# XMC4300 register map
Vendor: Infineon; File version: 0.5.1 (Superset device XMC4800)
CPU: CM4 r2p0, little endian, MPU, FPU, 6 interrupt priority bits
Registers are 32-bit, read-write, reset 0x0 unless marked. A register's access mark holds for its fields unless they carry their own. Offsets are from the block's base; [hi:lo] are bit positions.

## SDMMC — SD and Multimediacard Interface
Base 0x4801C000
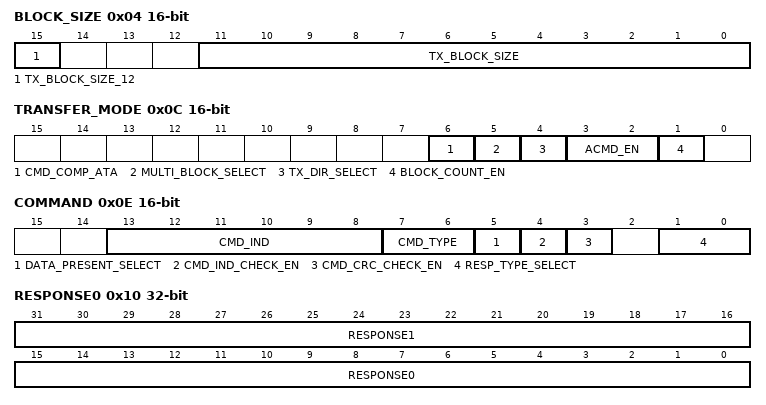
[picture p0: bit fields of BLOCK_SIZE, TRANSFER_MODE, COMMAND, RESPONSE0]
0x04 BLOCK_SIZE 16-bit
  [15] TX_BLOCK_SIZE_12 — Transfer Block Size 12th bit.
  [11:0] TX_BLOCK_SIZE — Transfer Block Size
0x06 BLOCK_COUNT 16-bit
  [15:0] BLOCK_COUNT — Blocks Count for Current Transfer
0x08 ARGUMENT1
  [31:0] ARGUMENT1 — Command Argument
0x0C TRANSFER_MODE 16-bit
  [6] CMD_COMP_ATA — Command Completion Signal Enable for CE-ATA Device
    1=Device will send command completion Signal; 0=Device will not send command completion Signal
  [5] MULTI_BLOCK_SELECT — Multi / Single Block Select
    0=Single Block; 1=Multiple Block
  [4] TX_DIR_SELECT — Data Transfer Direction Select
    0=Write (Host to Card); 1=Read (Card to Host)
  [3:2] ACMD_EN — Auto CMD Enable
    0=Auto Command Disabled; 1=Auto CMD12 Enable
  [1] BLOCK_COUNT_EN — Block Count Enable
    0=Disable; 1=Enable
0x0E COMMAND 16-bit
  [13:8] CMD_IND — Command Index
  [7:6] CMD_TYPE — Command Type
    0=Normal; 1=Suspend; 2=Resume; 3=Abort
  [5] DATA_PRESENT_SELECT
    0=No Data Present; 1=Data Present
  [4] CMD_IND_CHECK_EN — Command Index Check Enable
    0=Disable; 1=Enable
  [3] CMD_CRC_CHECK_EN — Command CRC Check Enable
    0=Disable; 1=Enable
  [1:0] RESP_TYPE_SELECT — Response Type Select
    0=No Response; 1=Response length 136; 2=Response length 48; 3=Response length 48 check Busy after response
0x10 RESPONSE0 ro
  [31:16] RESPONSE1, [15:0] RESPONSE0
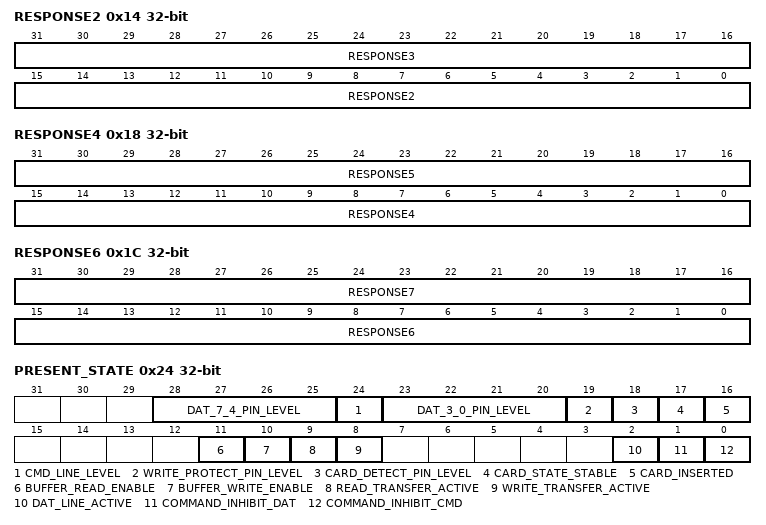
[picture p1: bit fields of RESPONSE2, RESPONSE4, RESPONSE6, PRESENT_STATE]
0x14 RESPONSE2 ro
  [31:16] RESPONSE3, [15:0] RESPONSE2
0x18 RESPONSE4 ro
  [31:16] RESPONSE5, [15:0] RESPONSE4
0x1C RESPONSE6 ro
  [31:16] RESPONSE7, [15:0] RESPONSE6
0x20 DATA_BUFFER
0x24 PRESENT_STATE ro
  [28:25] DAT_7_4_PIN_LEVEL — Line Signal Level
  [24] CMD_LINE_LEVEL — CMD Line Signal Level
  [23:20] DAT_3_0_PIN_LEVEL — Line Signal Level
  [19] WRITE_PROTECT_PIN_LEVEL — Write Protect Switch Pin Level
    0=Write protected (SDWP = 1); 1=Write enabled (SDWP = 0)
  [18] CARD_DETECT_PIN_LEVEL
    0=No Card present (SDCD = 1); 1=Card present (SDCD = 0)
  [17] CARD_STATE_STABLE
    0=Reset of Debouncing; 1=No Card or Inserted
  [16] CARD_INSERTED
    0=Reset or Debouncing or No Card; 1=Card Inserted
  [11] BUFFER_READ_ENABLE
    0=Read Disable; 1=Read Enable
  [10] BUFFER_WRITE_ENABLE
    0=Write Disable; 1=Write Enable
  [9] READ_TRANSFER_ACTIVE
    0=No valid data; 1=Transferring data
  [8] WRITE_TRANSFER_ACTIVE
    0=No valid data; 1=Transferring data
  [2] DAT_LINE_ACTIVE
    0=DAT line inactive; 1=DAT line active
  [1] COMMAND_INHIBIT_DAT
    0=Can issue command which uses the DAT line; 1=Cannot issue command which uses the DAT line
  [0] COMMAND_INHIBIT_CMD
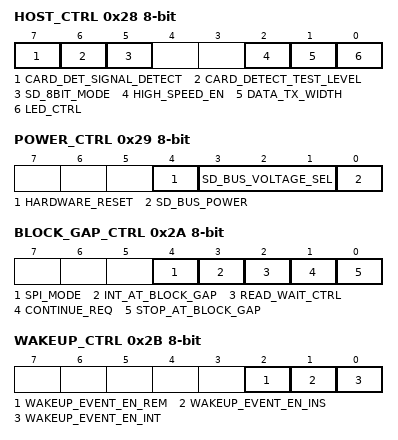
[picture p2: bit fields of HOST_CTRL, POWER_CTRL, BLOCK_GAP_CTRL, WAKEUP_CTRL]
0x28 HOST_CTRL 8-bit — Host Control Register
  [7] CARD_DET_SIGNAL_DETECT — Card detect signal detetction
    0=SDCD is selected (for normal use); 1=The card detect test level is selected
  [6] CARD_DETECT_TEST_LEVEL
    0=No Card; 1=Card Inserted
  [5] SD_8BIT_MODE — Extended Data Transfer Width
    0=Bus Width is selected by Data Transfer Width; 1=8-bit Bus Width
  [2] HIGH_SPEED_EN — High Speed Enable
    0=Normal Speed Mode; 1=High Speed Mode
  [1] DATA_TX_WIDTH — Data Transfer Width (SD1 or SD4)
    0=1 bit mode; 1=4-bit mode
  [0] LED_CTRL — LED Control
    0=LED off; 1=LED on
0x29 POWER_CTRL 8-bit — Power Control Register
  [4] HARDWARE_RESET
  [3:1] SD_BUS_VOLTAGE_SEL — SD Bus Voltage Select
    7=3.3V (Flattop.)
  [0] SD_BUS_POWER
    0=Power off; 1=Power on
0x2A BLOCK_GAP_CTRL 8-bit — Block Gap Control Register
  [4] SPI_MODE
    0=SD mode; 1=SPI mode
  [3] INT_AT_BLOCK_GAP — Interrupt At Block Gap
  [2] READ_WAIT_CTRL — Read Wait Control
    0=Disable Read Wait Control; 1=Enable Read Wait Control
  [1] CONTINUE_REQ — Continue Request
    0=Ignored; 1=Restart
  [0] STOP_AT_BLOCK_GAP — Stop At Block Gap Request
    0=Transfer; 1=Stop
0x2B WAKEUP_CTRL 8-bit — Wake-up Control Register
  [all] fields
    0=Disable; 1=Enable
  [2] WAKEUP_EVENT_EN_REM — Wakeup Event Enable On SD Card Removal
  [1] WAKEUP_EVENT_EN_INS — Wakeup Event Enable On SD Card Insertion
  [0] WAKEUP_EVENT_EN_INT — Wakeup Event Enable On Card Interrupt
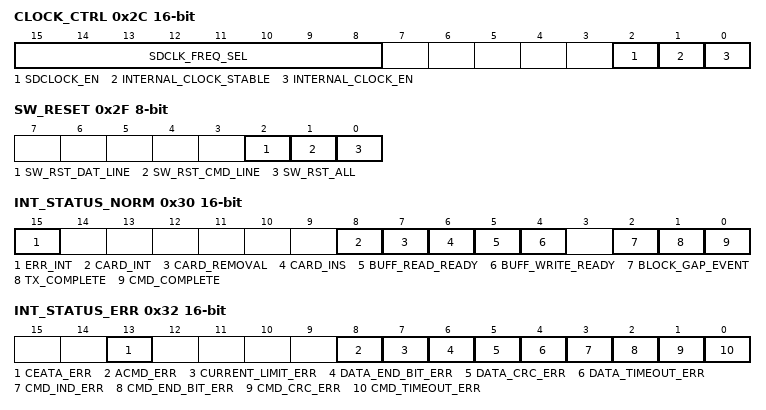
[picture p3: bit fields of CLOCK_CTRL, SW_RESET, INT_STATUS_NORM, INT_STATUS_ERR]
0x2C CLOCK_CTRL 16-bit access per field — Clock Control Register
  [15:8] SDCLK_FREQ_SEL rw — SDCLK Frequency Select
    0=base clock(10MHz-63MHz); 1=base clock divided by 2; 16=base clock divided by 32; 2=base clock divided by 4; 4=base clock divided by 8; 8=base clock divided by 16; 32=base clock divided by 64; 64=base clock divided by 128; 128=base clock divided by 256
  [2] SDCLOCK_EN rw — SD Clock Enable
    0=Disable; 1=Enable
  [1] INTERNAL_CLOCK_STABLE ro
    0=Not Ready; 1=Ready
  [0] INTERNAL_CLOCK_EN rw — Internal Clock Enable
    0=Stop; 1=Oscillate
0x2E TIMEOUT_CTRL 8-bit — Timeout Control Register
  [3:0] DAT_TIMEOUT_CNT_VAL — Data Timeout Counter Value
    0=TMCLK * 2^13; 1=TMCLK * 2^14; 14=TMCLK * 2^27
0x2F SW_RESET 8-bit — Software Reset Register
  [2] SW_RST_DAT_LINE — Software Reset for DAT Line
    0=Work; 1=Reset
  [1] SW_RST_CMD_LINE — Software Reset for CMD Line
    0=Work; 1=Reset
  [0] SW_RST_ALL — Software Reset for All
0x30 INT_STATUS_NORM 16-bit access per field — Normal Interrupt Status Register
  [15] ERR_INT ro — Error Interrupt
    0=No Error; 1=Error
  [8] CARD_INT ro — Card Interrupt
    0=No Card Interrupt; 1=Generate Card Interrupt
  [7] CARD_REMOVAL rw
    0=Card State Stable or Debouncing; 1=Card Removed
  [6] CARD_INS rw — Card Insertion
    0=Card State Stable or Debouncing; 1=Card Inserted
  [5] BUFF_READ_READY rw — Buffer Read Ready
    0=Not Ready to read Buffer; 1=Ready to read Buffer
  [4] BUFF_WRITE_READY rw — Buffer Write Ready
    0=Not Ready to Write Buffer; 1=Ready to Write Buffer
  [2] BLOCK_GAP_EVENT rw
    0=No Block Gap Event; 1=Transaction stopped at Block Gap
  [1] TX_COMPLETE rw — Transfer Complete
    0=No Data Transfer Complete; 1=Data Transfer Complete
  [0] CMD_COMPLETE rw — Command Complete
    0=No Command Complete; 1=Command Complete
0x32 INT_STATUS_ERR 16-bit — Error Interrupt Status Register
  [13] CEATA_ERR — Ceata Error Status
    0=no error; 1=error
  [8] ACMD_ERR — Auto CMD Error
    0=No Error; 1=Error
  [7] CURRENT_LIMIT_ERR — Current Limit Error
    0=No Error; 1=Power Fail
  [6] DATA_END_BIT_ERR — Data End Bit Error
    0=No Error; 1=Error
  [5] DATA_CRC_ERR — Data CRC Error
    0=No Error; 1=Error
  [4] DATA_TIMEOUT_ERR — Data Timeout Error
    0=No Error; 1=Timeout
  [3] CMD_IND_ERR — Command Index Error
    0=No Error; 1=Error
  [2] CMD_END_BIT_ERR — Command End Bit Error
    0=No Error; 1=End Bit Error Generated
  [1] CMD_CRC_ERR — Command CRC Error
    0=No Error; 1=CRC Error Generated
  [0] CMD_TIMEOUT_ERR — Command Timeout Error
    0=No Error; 1=Timeout
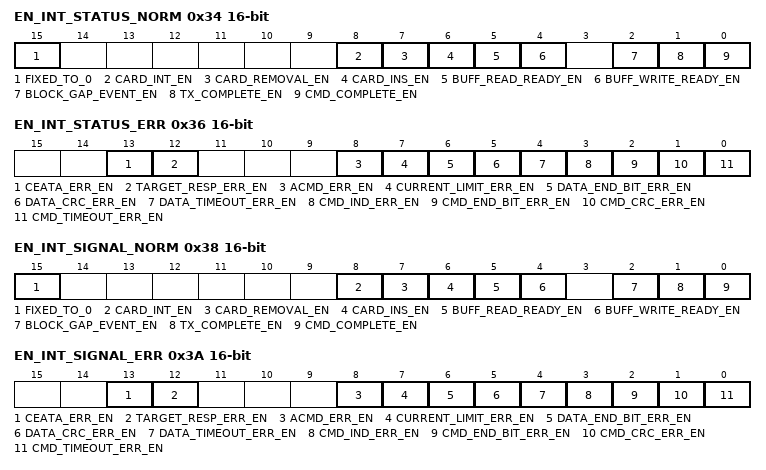
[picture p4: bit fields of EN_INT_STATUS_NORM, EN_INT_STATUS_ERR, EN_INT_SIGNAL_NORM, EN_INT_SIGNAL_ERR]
0x34 EN_INT_STATUS_NORM 16-bit access per field — Normal Interrupt Status Enable Register
  [15] FIXED_TO_0 ro
  [8] CARD_INT_EN rw — Card Interrupt Status Enable
    0=Masked; 1=Enabled
  [7] CARD_REMOVAL_EN rw — Card Removal Status Enable
    0=Masked; 1=Enabled
  [6] CARD_INS_EN rw — Card Insertion Status Enable
    0=Masked; 1=Enabled
  [5] BUFF_READ_READY_EN rw — Buffer Read Ready Status Enable
    0=Masked; 1=Enabled
  [4] BUFF_WRITE_READY_EN rw — Buffer Write Ready Status Enable
    0=Masked; 1=Enabled
  [2] BLOCK_GAP_EVENT_EN rw — Block Gap Event Status Enable
    0=Masked; 1=Enabled
  [1] TX_COMPLETE_EN rw — Transfer Complete Status Enable
    0=Masked; 1=Enabled
  [0] CMD_COMPLETE_EN rw — Command Complete Status Enable
    0=Masked; 1=Enabled
0x36 EN_INT_STATUS_ERR 16-bit — Error Interrupt Status Enable Register
  [all] fields
    0=Masked; 1=Enabled
  [13] CEATA_ERR_EN — Ceata Error Status Enable
  [12] TARGET_RESP_ERR_EN — Target Response Error Status Enable
  [8] ACMD_ERR_EN — Auto CMD12 Error Status Enable
  [7] CURRENT_LIMIT_ERR_EN — Current Limit Error Status Enable
  [6] DATA_END_BIT_ERR_EN — Data End Bit Error Status Enable
  [5] DATA_CRC_ERR_EN — Data CRC Error Status Enable
  [4] DATA_TIMEOUT_ERR_EN — Data Timeout Error Status Enable
  [3] CMD_IND_ERR_EN — Command Index Error Status Enable
  [2] CMD_END_BIT_ERR_EN — Command End Bit Error Status Enable
  [1] CMD_CRC_ERR_EN — Command CRC Error Status Enable
  [0] CMD_TIMEOUT_ERR_EN — Command Timeout Error Status Enable
0x38 EN_INT_SIGNAL_NORM 16-bit access per field — Normal Interrupt Signal Enable Register
  [15] FIXED_TO_0 ro
  [8] CARD_INT_EN rw — Card Interrupt Signal Enable
    0=Masked; 1=Enabled
  [7] CARD_REMOVAL_EN rw — Card Removal Signal Enable
    0=Masked; 1=Enabled
  [6] CARD_INS_EN rw — Card Insertion Signal Enable
    0=Masked; 1=Enabled
  [5] BUFF_READ_READY_EN rw — Buffer Read Ready Signal Enable
    0=Masked; 1=Enabled
  [4] BUFF_WRITE_READY_EN rw — Buffer Write Ready Signal Enable
    0=Masked; 1=Enabled
  [2] BLOCK_GAP_EVENT_EN rw — Block Gap Event Signal Enable
    0=Masked; 1=Enabled
  [1] TX_COMPLETE_EN rw — Transfer Complete Signal Enable
    0=Masked; 1=Enabled
  [0] CMD_COMPLETE_EN rw — Command Complete Signal Enable
    0=Masked; 1=Enabled
0x3A EN_INT_SIGNAL_ERR 16-bit — Error Interrupt Signal Enable Register
  [all] fields
    0=Masked; 1=Enabled
  [13] CEATA_ERR_EN — Ceata Error Signal Enable
  [12] TARGET_RESP_ERR_EN — Target Response Error Signal Enable
  [8] ACMD_ERR_EN — Auto CMD12 Error Signal Enable
  [7] CURRENT_LIMIT_ERR_EN — Current Limit Error Signal Enable
  [6] DATA_END_BIT_ERR_EN — Data End Bit Error Signal Enable
  [5] DATA_CRC_ERR_EN — Data CRC Error Signal Enable
  [4] DATA_TIMEOUT_ERR_EN — Data Timeout Error Signal Enable
  [3] CMD_IND_ERR_EN — Command Index Error Signal Enable
  [2] CMD_END_BIT_ERR_EN — Command End Bit Error Signal Enable
  [1] CMD_CRC_ERR_EN — Command CRC Error Signal Enable
  [0] CMD_TIMEOUT_ERR_EN — Command Timeout Error Signal Enable
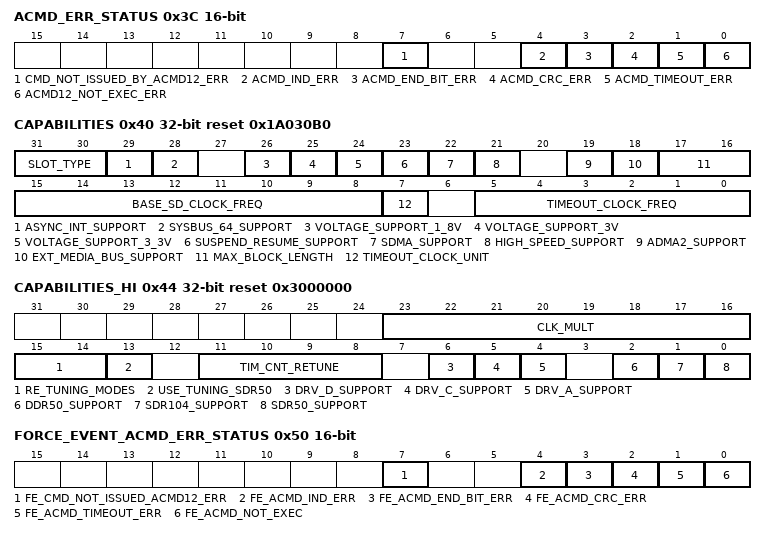
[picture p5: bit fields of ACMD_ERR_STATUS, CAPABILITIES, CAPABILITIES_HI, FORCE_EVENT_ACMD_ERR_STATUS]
0x3C ACMD_ERR_STATUS 16-bit ro — Auto CMD Error Status Register
  [7] CMD_NOT_ISSUED_BY_ACMD12_ERR — Command Not Issued By Auto CMD12 Error
    0=No Error; 1=Not Issued
  [4] ACMD_IND_ERR — Auto CMD Index Error
    0=No Error; 1=Error
  [3] ACMD_END_BIT_ERR — Auto CMD End Bit Error
    0=No Error; 1=End Bit Error Generated
  [2] ACMD_CRC_ERR — Auto CMD CRC Error
    0=No Error; 1=CRC Error Generated
  [1] ACMD_TIMEOUT_ERR — Auto CMD Timeout Error
    0=No Error; 1=Timeout
  [0] ACMD12_NOT_EXEC_ERR — Auto CMD12 Not Executed
    0=Executed; 1=Not Executed
0x40 CAPABILITIES ro reset 0x1A030B0
  [31:30] SLOT_TYPE
    0=Removable Card Slot
  [29] ASYNC_INT_SUPPORT — Asynchronous Interrupt Support
    0=Asynchronous Interrupt not supported
  [28] SYSBUS_64_SUPPORT — 64-bit System Bus Support
    0=Does not support 64-bit system address
  [26] VOLTAGE_SUPPORT_1_8V
    0=1.8V not supported
  [25] VOLTAGE_SUPPORT_3V — Voltage Support 3.0V
    0=3.0V not supported
  [24] VOLTAGE_SUPPORT_3_3V
    1=3.3V supported
  [23] SUSPEND_RESUME_SUPPORT
    1=Supported
  [22] SDMA_SUPPORT
    0=SDMA not supported
  [21] HIGH_SPEED_SUPPORT
    1=High Speed supported
  [19] ADMA2_SUPPORT
    0=ADMA not supported
  [18] EXT_MEDIA_BUS_SUPPORT — Extended Media Bus Support
    0=Extended Media Bus not supported
  [17:16] MAX_BLOCK_LENGTH
    0=512 byte
  [15:8] BASE_SD_CLOCK_FREQ — Base Clock Frequency for SD Clock
    48=48 MHz
  [7] TIMEOUT_CLOCK_UNIT
    1=MHz
  [5:0] TIMEOUT_CLOCK_FREQ — Timeout Clock Frequency
    48=48 MHz
0x44 CAPABILITIES_HI ro reset 0x3000000 — Capabilities Register High
  [23:16] CLK_MULT — Clock Multiplier
    0=Clock Multiplier not supported
  [15:14] RE_TUNING_MODES
    0=Mode 1
  [13] USE_TUNING_SDR50 — Use Tuning for SDR50
    0=SDR50 does not require tuning
  [11:8] TIM_CNT_RETUNE — Timer count for Re-Tuning
    0=Get information via other source
  [6] DRV_D_SUPPORT — Driver Type D Support
    0=Driver Type D is not supported
  [5] DRV_C_SUPPORT — Driver Type C Support
    0=Driver Type C is not supported
  [4] DRV_A_SUPPORT — Driver Type A Support
    0=Driver Type A is not supported
  [2] DDR50_SUPPORT
    0=DDR50 is not supported
  [1] SDR104_SUPPORT
    0=SDR104 is not supported
  [0] SDR50_SUPPORT
    0=SDR50 is not supported
0x48 MAX_CURRENT_CAP ro reset 0x1 — Maximum Current Capabilities Register
  [7:0] MAX_CURRENT_FOR_3_3V — Maximum Current for 3.3V
0x50 FORCE_EVENT_ACMD_ERR_STATUS 16-bit wo — Force Event Register for Auto CMD Error Status
  [all] fields
    0=No interrupt; 1=Interrupt is generated
  [7] FE_CMD_NOT_ISSUED_ACMD12_ERR — Force Event for CMD not issued by Auto CMD12 Error
  [4] FE_ACMD_IND_ERR — Force Event for Auto CMD Index Error
  [3] FE_ACMD_END_BIT_ERR — Force Event for Auto CMD End bit Error
  [2] FE_ACMD_CRC_ERR — Force Event for Auto CMD CRC Error
  [1] FE_ACMD_TIMEOUT_ERR — Force Event for Auto CMD timeout Error
  [0] FE_ACMD_NOT_EXEC — Force Event for Auto CMD12 NOT Executed
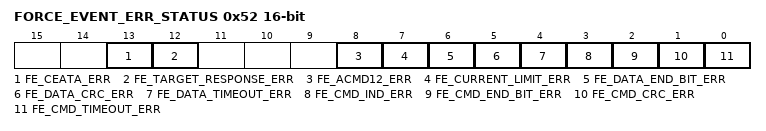
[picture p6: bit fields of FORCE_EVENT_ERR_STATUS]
0x52 FORCE_EVENT_ERR_STATUS 16-bit wo — Force Event Register for Error Interrupt Status
  [all] fields
    0=No interrupt; 1=Interrupt is generated
  [13] FE_CEATA_ERR — Force Event for Ceata Error
  [12] FE_TARGET_RESPONSE_ERR — Force event for Target Response Error
  [8] FE_ACMD12_ERR — Force Event for Auto CMD Error
  [7] FE_CURRENT_LIMIT_ERR — Force Event for Current Limit Error
  [6] FE_DATA_END_BIT_ERR — Force Event for Data End Bit Error
  [5] FE_DATA_CRC_ERR — Force Event for Data CRC Error
  [4] FE_DATA_TIMEOUT_ERR — Force Event for Data Timeout Error
  [3] FE_CMD_IND_ERR — Force Event for Command Index Error
  [2] FE_CMD_END_BIT_ERR — Force Event for Command End Bit Error
  [1] FE_CMD_CRC_ERR — Force Event for Command CRC Error
  [0] FE_CMD_TIMEOUT_ERR — Force Event for Command Timeout Error
0x74 DEBUG_SEL wo — Debug Selection Register
  [0] DEBUG_SEL
    0=receiver module and fifo_ctrl module signals are probed out; 1=cmd register, Interrupt status, transmitter module and clk sdcard signals are probed out
0xF0 SPI — SPI Interrupt Support Register
  [7:0] SPI_INT_SUPPORT
0xFC SLOT_INT_STATUS 16-bit ro — Slot Interrupt Status Register
  [7:0] SLOT_INT_STATUS — Interrupt Signal for Card Slot
    0=Slot 1
